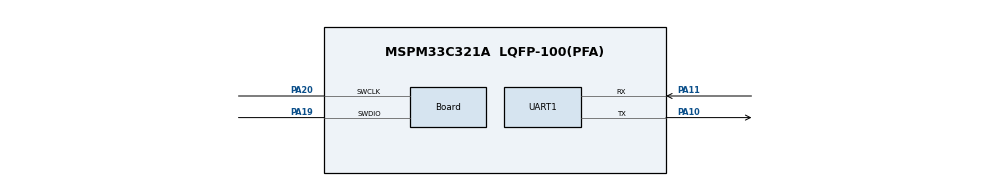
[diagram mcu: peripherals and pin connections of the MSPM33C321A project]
//@cliArgs --device "MSPM33C321A" --package "LQFP-100(PFA)" --part "Default"
//@v2CliArgs --device "MSPM33C321A" --package "LQFP-100(PFA)"
// @cliArgs --board /ti/boards/LP_MSPM33C321A --rtos nortos

const DMA    = scripting.addModule("/ti/driverlib/DMA", {}, false);
const DMA1   = DMA.addInstance();
const SYSCTL = scripting.addModule("/ti/driverlib/SYSCTL");
const UART   = scripting.addModule("/ti/driverlib/UART", {}, false);
const UART1  = UART.addInstance();
const Board  = scripting.addModule("/ti/driverlib/Board", {}, false);

DMA1.$name = "DMA0";

Board.peripheral.$assign          = "DEBUGSS";
Board.peripheral.swclkPin.$assign = "PA20";
Board.peripheral.swdioPin.$assign = "PA19";

SYSCTL.forceDefaultClkConfig = true;
SYSCTL.peripheral.$assign    = "SYSCTL";

/* UART on the XDS110 back-channel pins. Baud here is only a placeholder: main.c
 * re-programs the divisor from the single build-time define USART_BAUD. */
UART1.$name                             = "UART_0";
UART1.targetBaudRate                    = 115200;
UART1.enableFIFO                        = true;
UART1.rxFifoThreshold                   = "DL_UART_RX_FIFO_LEVEL_ONE_ENTRY";
UART1.txFifoThreshold                   = "DL_UART_TX_FIFO_LEVEL_EMPTY";
UART1.peripheral.$assign                = "UC12";
UART1.peripheral.rxPin.$assign          = "PA11";
UART1.peripheral.txPin.$assign          = "PA10";
UART1.txPinConfig.$name                 = "ti_driverlib_gpio_GPIOPinGeneric0";
UART1.txPinConfig.enableConfig          = true;
UART1.rxPinConfig.$name                 = "ti_driverlib_gpio_GPIOPinGeneric1";
UART1.rxPinConfig.enableConfig          = true;
UART1.rxPinConfig.internalResistor      = "PULL_UP";
UART1.enabledDMARXTriggers              = "DL_UART_DMA_INTERRUPT_RX";
UART1.enabledDMATXTriggers              = "DL_UART_DMA_INTERRUPT_TX";
UART1.enabledInterrupts                 = ["DMA_DONE_RX","DMA_DONE_TX"];
UART1.DMA_CHANNEL_RX.$name              = "CH1";
UART1.DMA_CHANNEL_RX.addressMode        = "b2b";
UART1.DMA_CHANNEL_RX.srcLength          = "BYTE";
UART1.DMA_CHANNEL_RX.dstLength          = "BYTE";
UART1.DMA_CHANNEL_RX.srcIncDec          = "UNCHANGED";
UART1.DMA_CHANNEL_RX.transferMode       = "FULL_CH_REPEAT_SINGLE";
UART1.DMA_CHANNEL_RX.transferSize       = 64;
UART1.DMA_CHANNEL_RX.peripheral.$assign = "DMA0_CH1";
UART1.DMA_CHANNEL_TX.$name              = "CH0";
UART1.DMA_CHANNEL_TX.addressMode        = "b2b";
UART1.DMA_CHANNEL_TX.srcLength          = "BYTE";
UART1.DMA_CHANNEL_TX.dstLength          = "BYTE";
UART1.DMA_CHANNEL_TX.dstIncDec          = "UNCHANGED";
UART1.DMA_CHANNEL_TX.peripheral.$assign = "DMA0_CH0";
